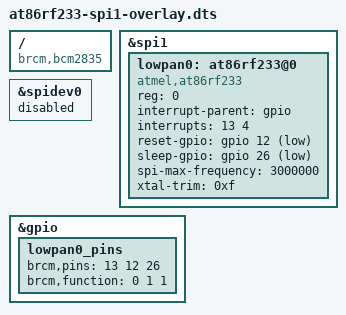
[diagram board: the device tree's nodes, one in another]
/dts-v1/;
/plugin/;

/* Overlay for Atmel AT86RF233 IEEE 802.15.4 WPAN transceiver on spi1.0(default)/spi1.1 */

/ {
	compatible = "brcm,bcm2835", "brcm,bcm2836", "brcm,bcm2708", "brcm,bcm2709";

	fragment@0 {
		target = <&spi1>;
		__overlay__ {
			#address-cells = <1>;
			#size-cells = <0>;

			status = "okay";

			lowpan0: at86rf233@0 {
				compatible = "atmel,at86rf233";
				reg = <0>;		/* CE0 default */
				interrupt-parent = <&gpio>;
				interrupts = <13 4>; /* active high */
				reset-gpio = <&gpio 12 1>;
				sleep-gpio = <&gpio 26 1>;
				spi-max-frequency = <3000000>;
				xtal-trim = /bits/ 8 <0xf>;
				status = "okay";
			};
		};
	};

	fragment@1 {
		target = <&spidev0>;
		__overlay__ {
			status = "disabled";
		};
	};

	fragment@2 {
		target = <&gpio>;
		__overlay__ {
			lowpan0_pins: lowpan0_pins {
				brcm,pins = <13 12 26>;
				brcm,function = <0 1 1>; /* in out out */
			};
		};
	};

	__overrides__ {
		ce = <&lowpan0>, "reg:0";
		interrupt = <&lowpan0>, "interrupts:0",
			<&lowpan0_pins>, "brcm,pins:0";
		reset     = <&lowpan0>, "reset-gpio:4",
			<&lowpan0_pins>, "brcm,pins:4";
		sleep     = <&lowpan0>, "sleep-gpio:4",
			<&lowpan0_pins>, "brcm,pins:8";
		speed     = <&lowpan0>, "spi-max-frequency:0";
		trim      = <&lowpan0>, "xtal-trim.0";
	};
};
